# KM1M7CF14 register map
Vendor: Nuvoton Technology Corporation Japan; Series: KM1M7CF; File version: 1.0.3
CPU: CM7 r1p2, little endian, MPU, FPU, double-precision FPU, I-cache, D-cache, ITCM, DTCM, 4 interrupt priority bits
Registers are 32-bit, read-write, no defined reset value unless marked. A register's access mark holds for its fields unless they carry their own. Offsets are from the block's base; [hi:lo] are bit positions; {n}, {i} and the like mark numbered series; 'fields as' and 'values as' point back to an identical list.

## DMAC — DMA Controller
Base 0x40200000
{0x0+0x40*i} DMA{i}SRC (i=0..7) — DMA{i} Source Address Register
  [31:0] SRC — DMA transfer source address
{0x4+0x40*i} DMA{i}DST (i=0..7) — DMA{i} Destination Address Register
  [31:0] DST — DMA transfer destination address
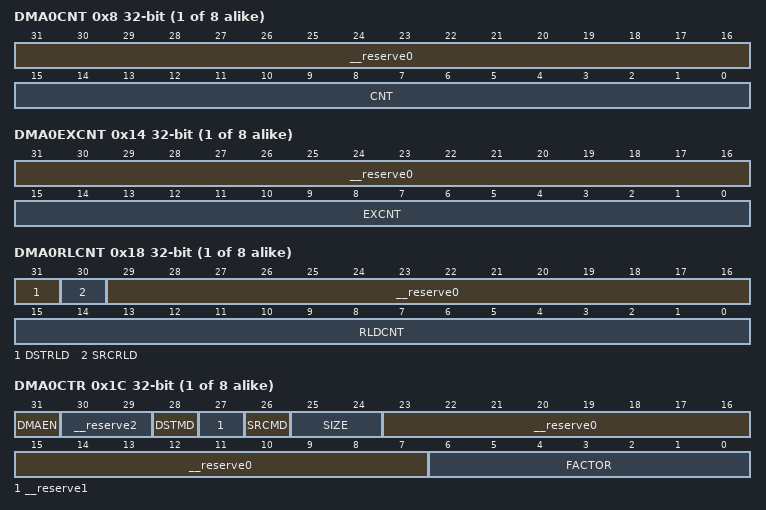
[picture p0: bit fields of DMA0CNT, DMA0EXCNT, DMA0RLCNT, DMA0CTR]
{0x8+0x40*i} DMA{i}CNT access per field (i=0..7) — DMA{i} Transfer Word Count Register
  [31:16] __reserve0 ro — "0" is always read out.
  [15:0] CNT rw — DMA transfer word count
{0xC+0x40*i} DMA{i}EXSRC (i=0..7) — DMA{i} Execution Source Address Register
  [31:0] EXSRC — During DMA transfer, the transfer source address is held.
{0x10+0x40*i} DMA{i}EXDST (i=0..7) — DMA{i} Execution Destination Address Register
  [31:0] EXDST — During DMA transfer, the transfer destination address is held.
{0x14+0x40*i} DMA{i}EXCNT access per field (i=0..7) — Executio{i} Transfer Word Count Register
  [31:16] __reserve0 ro — "0" is always read out.
  [15:0] EXCNT rw — During DMA transfer, the DMA transfer word count is held.
{0x18+0x40*i} DMA{i}RLCNT access per field (i=0..7) — DMA{i} Reload Counter
  [31] DSTRLD rw — Load enable (during reload operation)
  [30] SRCRLD rw — Load enable (during reload operation)
  [29:16] __reserve0 ro — "0" is always read out.
  [15:0] RLDCNT rw — The number of times of reloading
{0x1C+0x40*i} DMA{i}CTR access per field (i=0..7) — DMA Co{i}trol Register
  [31] DMAEN rw — DMA transfer enable
  [30:29] __reserve2 ro — "0" is always read out.
  [28] DSTMD rw — DMA transfer addressing mode on destination address
  [27] __reserve1 ro — "0" is always read out.
  [26] SRCMD rw — DMA transfer addressing mode on source address
  [25:24] SIZE rw — DMA transfer unit
  [23:7] __reserve0 ro — "0" is always read out.
  [6:0] FACTOR rw — DMA transfer request
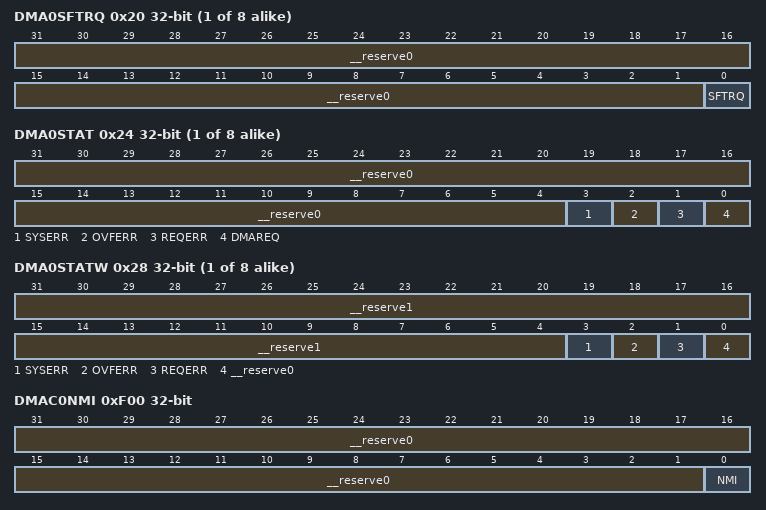
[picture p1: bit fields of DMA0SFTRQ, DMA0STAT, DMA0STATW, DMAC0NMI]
{0x20+0x40*i} DMA{i}SFTRQ access per field (i=0..7) — DMA{i} Software Request Register
  [31:1] __reserve0 ro — "0" is always read out.
  [0] SFTRQ wo — DMA request by software
{0x24+0x40*i} DMA{i}STAT ro (i=0..7) — DMA Status Read Register
  [31:4] __reserve0 — "0" is always read out.
  [3] SYSERR — System error bit
  [2] OVFERR — DMA transfer request overflow bit
  [1] REQERR — Disabled DMA transfer request error bit
  [0] DMAREQ — DMA transfer status
{0x28+0x40*i} DMA{i}STATW access per field (i=0..7) — DMA Status Clear Register
  [31:4] __reserve1 ro — "0" is always read out.
  [3] SYSERR wo — Clear the system error bit
  [2] OVFERR wo — Clear the DMA transfer request overflow bit
  [1] REQERR wo — Clear the DMA transfer request error bit
  [0] __reserve0 ro — "0" is always read out.
0xF00 DMAC0NMI ro — DMA0NMI Status Read Register
  [31:1] __reserve0 — "0" is always read out.
  [0] NMI — NMI detection bit (module m)
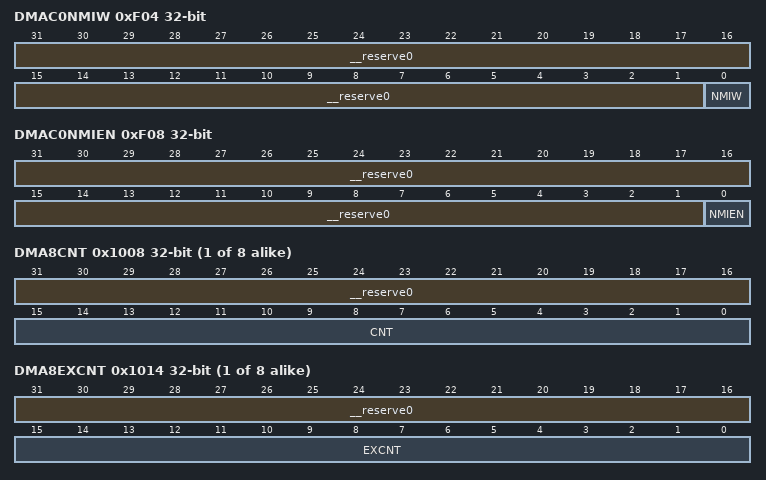
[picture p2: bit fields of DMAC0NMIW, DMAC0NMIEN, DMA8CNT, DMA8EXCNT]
0xF04 DMAC0NMIW access per field — DMA0NMI Status Clear Register
  [31:1] __reserve0 ro — "0" is always read out.
  [0] NMIW wo — Clear the NMI detection bit (module m)
0xF08 DMAC0NMIEN access per field — DMA0NMI Enable Register
  [31:1] __reserve0 ro — "0" is always read out.
  [0] NMIEN rw — DMA transfer discontinuity (module m) when NMI is detected
{0xE00+0x40*i} DMA{i}SRC (i=8..15) — DMA{i} Source Address Register
  [31:0] SRC — DMA transfer source address
{0xE04+0x40*i} DMA{i}DST (i=8..15) — DMA{i} Destination Address Register
  [31:0] DST — DMA transfer destination address
{0xE08+0x40*i} DMA{i}CNT access per field (i=8..15) — DMA{i} Transfer Word Count Register
  fields as DMA0CNT
{0xE0C+0x40*i} DMA{i}EXSRC (i=8..15) — DMA{i} Execution Source Address Register
  fields as DMA0EXSRC
{0xE10+0x40*i} DMA{i}EXDST (i=8..15) — DMA{i} Execution Destination Address Register
  fields as DMA0EXDST
{0xE14+0x40*i} DMA{i}EXCNT access per field (i=8..15) — Executio{i} Transfer Word Count Register
  fields as DMA0EXCNT
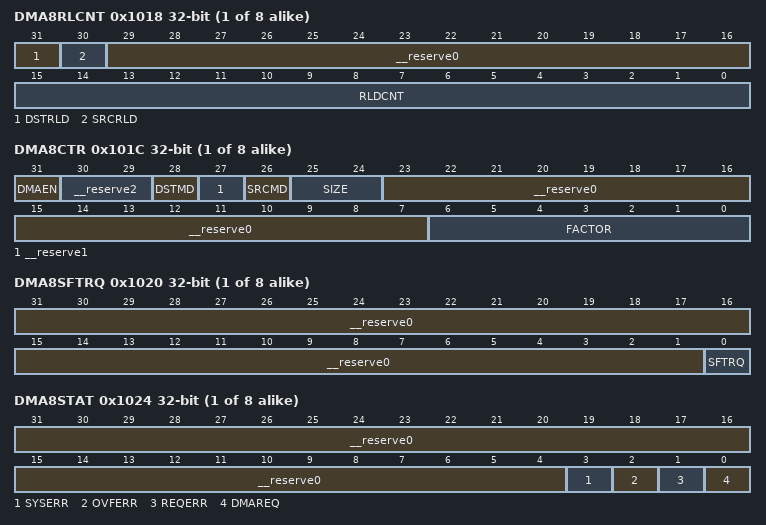
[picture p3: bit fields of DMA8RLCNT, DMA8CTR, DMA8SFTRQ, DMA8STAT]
{0xE18+0x40*i} DMA{i}RLCNT access per field (i=8..15) — DMA{i} Reload Counter
  fields as DMA0RLCNT
{0xE1C+0x40*i} DMA{i}CTR access per field (i=8..15) — DMA Co{i}trol Register
  fields as DMA0CTR
{0xE20+0x40*i} DMA{i}SFTRQ access per field (i=8..15) — DMA{i} Software Request Register
  fields as DMA0SFTRQ
{0xE24+0x40*i} DMA{i}STAT ro (i=8..15) — DMA Status Read Register
  fields as DMA0STAT
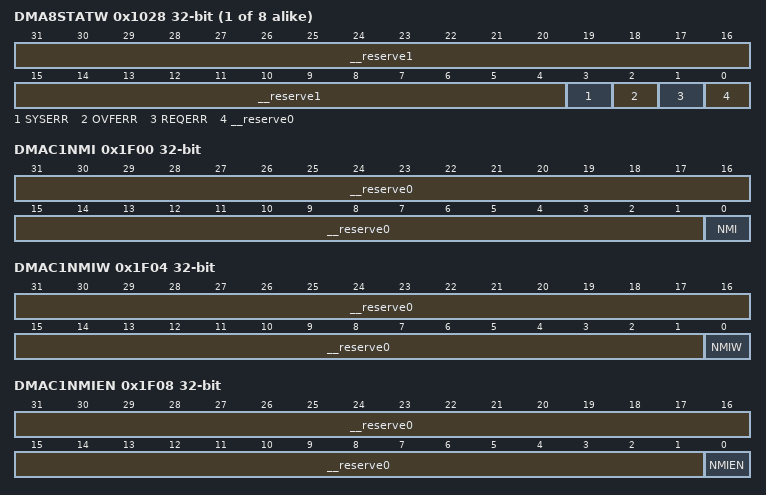
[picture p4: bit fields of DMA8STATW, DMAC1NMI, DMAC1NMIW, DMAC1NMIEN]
{0xE28+0x40*i} DMA{i}STATW access per field (i=8..15) — DMA Status Clear Register
  fields as DMA0STATW
0x1F00 DMAC1NMI ro — DMA1NMI Status Read Register
  fields as DMAC0NMI
0x1F04 DMAC1NMIW access per field — DMA1NMI Status Clear Register
  fields as DMAC0NMIW
0x1F08 DMAC1NMIEN access per field — DMA1NMI Enable Register
  fields as DMAC0NMIEN
